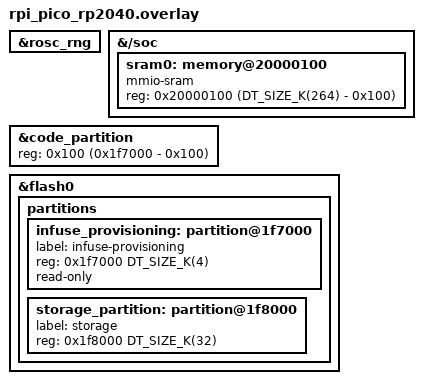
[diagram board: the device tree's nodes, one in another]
/*
 * Copyright (c) 2026 Embeint Holdings Pty Ltd
 * SPDX-License-Identifier: FSL-1.1-ALv2
 */

#include "rpi_pico_common.dtsi"

/* ROSC is available through the entropy API, without cryptographic guarantees. */
&rosc_rng {
	status = "okay";
};

/delete-node/ &sram0;

&{/soc} {
	sram0: memory@20000100 {
		compatible = "mmio-sram";
		reg = <0x20000100 (DT_SIZE_K(264) - 0x100)>;
	};
};

/* Preserve the first 256 bytes containing boot2. */
&code_partition {
	reg = <0x100 (0x1f7000 - 0x100)>;
};

&flash0 {
	partitions {
		infuse_provisioning: partition@1f7000 {
			label = "infuse-provisioning";
			reg = <0x1f7000 DT_SIZE_K(4)>;
			read-only;
		};

		storage_partition: partition@1f8000 {
			label = "storage";
			reg = <0x1f8000 DT_SIZE_K(32)>;
		};
	};
};
